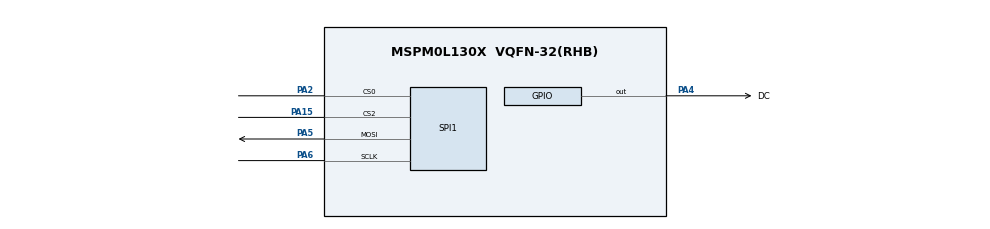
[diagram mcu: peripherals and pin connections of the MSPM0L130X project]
/**
 * @cliArgs --device "MSPM0L130X" --package "VQFN-32(RHB)" --part "Default" --product "mspm0_sdk@1.20.01.06"
 * @versions {"tool":"1.18.1+3343"}
 */

/**
 * Import the modules used in this configuration.
 */
const Board  = scripting.addModule("/ti/driverlib/Board");
const GPIO   = scripting.addModule("/ti/driverlib/GPIO", {}, false);
const GPIO1  = GPIO.addInstance();
const GPIO2  = GPIO.addInstance();
const GPIO3  = GPIO.addInstance();
const SPI    = scripting.addModule("/ti/driverlib/SPI", {}, false);
const SPI1   = SPI.addInstance();
const SYSCTL = scripting.addModule("/ti/driverlib/SYSCTL");
const TIMER  = scripting.addModule("/ti/driverlib/TIMER", {}, false);
const TIMER1 = TIMER.addInstance();
const UART   = scripting.addModule("/ti/driverlib/UART", {}, false);
const UART1  = UART.addInstance();

/**
 * Write custom configuration values to the imported modules.
 */
const gate6  = system.clockTree["MFCLKGATE"];
gate6.enable = true;

const gate7  = system.clockTree["MFPCLKGATE"];
gate7.enable = true;


GPIO1.$name                         = "OLED";
GPIO1.associatedPins[0].$name       = "DC";
GPIO1.associatedPins[0].pin.$assign = "PA4";

GPIO2.$name                              = "MAT_KEY";
GPIO2.associatedPins.create(8);
GPIO2.associatedPins[0].$name            = "ROW0";
GPIO2.associatedPins[0].assignedPin      = "0";
GPIO2.associatedPins[0].assignedPort     = "PORTA";
GPIO2.associatedPins[1].$name            = "ROW1";
GPIO2.associatedPins[1].assignedPin      = "1";
GPIO2.associatedPins[2].$name            = "ROW2";
GPIO2.associatedPins[2].assignedPin      = "7";
GPIO2.associatedPins[3].$name            = "ROW3";
GPIO2.associatedPins[3].assignedPin      = "12";
GPIO2.associatedPins[4].$name            = "COL0";
GPIO2.associatedPins[4].direction        = "INPUT";
GPIO2.associatedPins[4].internalResistor = "PULL_UP";
GPIO2.associatedPins[4].assignedPin      = "13";
GPIO2.associatedPins[5].internalResistor = "PULL_UP";
GPIO2.associatedPins[5].assignedPin      = "14";
GPIO2.associatedPins[5].$name            = "COL1";
GPIO2.associatedPins[5].direction        = "INPUT";
GPIO2.associatedPins[6].$name            = "COL2";
GPIO2.associatedPins[6].internalResistor = "PULL_UP";
GPIO2.associatedPins[6].assignedPin      = "17";
GPIO2.associatedPins[6].direction        = "INPUT";
GPIO2.associatedPins[7].$name            = "COL3";
GPIO2.associatedPins[7].internalResistor = "PULL_UP";
GPIO2.associatedPins[7].direction        = "INPUT";
GPIO2.associatedPins[7].assignedPin      = "18";

GPIO3.$name                         = "LED";
GPIO3.associatedPins[0].$name       = "LED0";
GPIO3.associatedPins[0].assignedPin = "3";

SPI1.$name                              = "SPI_OLED";
SPI1.direction                          = "PICO";
SPI1.chipSelect                         = ["0","2"];
SPI1.peripheral.$assign                 = "SPI0";
SPI1.peripheral.sclkPin.$assign         = "PA6";
SPI1.peripheral.mosiPin.$assign         = "PA5";
SPI1.peripheral.cs0Pin.$assign          = "PA2";
SPI1.peripheral.cs2Pin.$assign          = "PA15";
SPI1.sclkPinConfig.$name                = "ti_driverlib_gpio_GPIOPinGeneric0";
SPI1.sclkPinConfig.direction            = scripting.forceWrite("OUTPUT");
SPI1.sclkPinConfig.onlyInternalResistor = scripting.forceWrite(false);
SPI1.sclkPinConfig.passedPeripheralType = scripting.forceWrite("Digital");
SPI1.mosiPinConfig.$name                = "ti_driverlib_gpio_GPIOPinGeneric1";
SPI1.mosiPinConfig.direction            = scripting.forceWrite("OUTPUT");
SPI1.mosiPinConfig.hideOutputInversion  = scripting.forceWrite(false);
SPI1.mosiPinConfig.onlyInternalResistor = scripting.forceWrite(false);
SPI1.mosiPinConfig.passedPeripheralType = scripting.forceWrite("Digital");
SPI1.cs0PinConfig.$name                 = "ti_driverlib_gpio_GPIOPinGeneric3";
SPI1.cs0PinConfig.direction             = scripting.forceWrite("OUTPUT");
SPI1.cs0PinConfig.hideOutputInversion   = scripting.forceWrite(false);
SPI1.cs0PinConfig.onlyInternalResistor  = scripting.forceWrite(false);
SPI1.cs0PinConfig.passedPeripheralType  = scripting.forceWrite("Digital");
SPI1.cs2PinConfig.$name                 = "ti_driverlib_gpio_GPIOPinGeneric2";

SYSCTL.MFCLKEn     = true;
SYSCTL.MFPCLKEn    = true;
SYSCTL.clockTreeEn = true;

TIMER1.$name            = "TIMER_0";
TIMER1.timerClkSrc      = "MFCLK";
TIMER1.timerClkPrescale = 100;
TIMER1.timerPeriod      = "1000 ms";
TIMER1.interrupts       = ["ZERO"];

UART1.$name              = "UART_0";
UART1.uartClkSrc         = "MFCLK";
UART1.targetBaudRate     = 115200;
UART1.peripheral.$assign = "UART1";
UART1.txPinConfig.$name  = "ti_driverlib_gpio_GPIOPinGeneric4";
UART1.rxPinConfig.$name  = "ti_driverlib_gpio_GPIOPinGeneric5";

/**
 * Pinmux solution for unlocked pins/peripherals. This ensures that minor changes to the automatic solver in a future
 * version of the tool will not impact the pinmux you originally saw.  These lines can be completely deleted in order to
 * re-solve from scratch.
 */
Board.peripheral.$suggestSolution            = "DEBUGSS";
Board.peripheral.swclkPin.$suggestSolution   = "PA20";
Board.peripheral.swdioPin.$suggestSolution   = "PA19";
GPIO2.associatedPins[0].pin.$suggestSolution = "PA0";
GPIO2.associatedPins[1].pin.$suggestSolution = "PA1";
GPIO2.associatedPins[2].pin.$suggestSolution = "PA7";
GPIO2.associatedPins[3].pin.$suggestSolution = "PA12";
GPIO2.associatedPins[4].pin.$suggestSolution = "PA13";
GPIO2.associatedPins[5].pin.$suggestSolution = "PA14";
GPIO2.associatedPins[6].pin.$suggestSolution = "PA17/OPA1.IN0-";
GPIO2.associatedPins[7].pin.$suggestSolution = "PA18";
GPIO3.associatedPins[0].pin.$suggestSolution = "PA3";
TIMER1.peripheral.$suggestSolution           = "TIMG0";
UART1.peripheral.rxPin.$suggestSolution      = "PA11";
UART1.peripheral.txPin.$suggestSolution      = "PA10";
